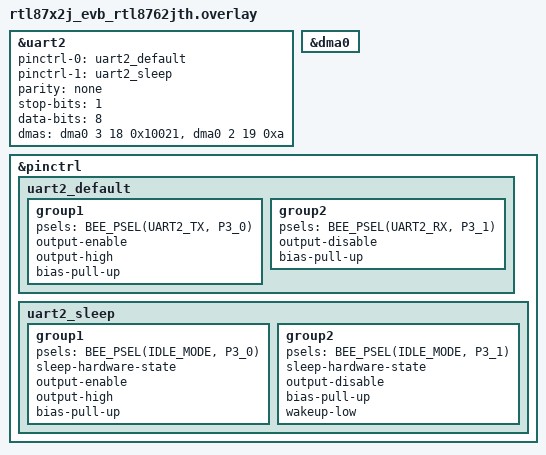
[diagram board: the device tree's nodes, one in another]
/*
 * Copyright (c) 2026, Realtek Semiconductor Corporation
 *
 * SPDX-License-Identifier: Apache-2.0
 */

&uart2 {
	pinctrl-0 = <&uart2_default>;
	pinctrl-1 = <&uart2_sleep>;
	pinctrl-names = "default", "sleep";
	status = "okay";
	parity = "none";
	stop-bits = "1";
	data-bits = <8>;
	dmas = <&dma0 3 18 0x10021>, <&dma0 2 19 0xa>;
	dma-names = "tx", "rx";
};

&dma0 {
	status = "okay";
};

&pinctrl {
	uart2_default: uart2_default {
		group1 {
			psels = <BEE_PSEL(UART2_TX, P3_0)>;
			output-enable;
			output-high;
			bias-pull-up;
		};

		group2 {
			psels = <BEE_PSEL(UART2_RX, P3_1)>;
			output-disable;
			bias-pull-up;
		};
	};

	uart2_sleep: uart2_sleep {
		group1 {
			psels = <BEE_PSEL(IDLE_MODE, P3_0)>;
			sleep-hardware-state;
			output-enable;
			output-high;
			bias-pull-up;
		};

		group2 {
			psels = <BEE_PSEL(IDLE_MODE, P3_1)>;
			sleep-hardware-state;
			output-disable;
			bias-pull-up;
			wakeup-low;
		};
	};
};
